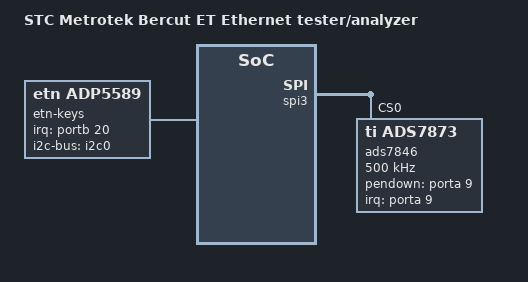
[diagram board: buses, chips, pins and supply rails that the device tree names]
/*
 * Copyright Altera Corporation (C) 2012,2014. All rights reserved.
 *
 * This program is free software; you can redistribute it and/or modify
 * it under the terms and conditions of the GNU General Public License,
 * version 2, as published by the Free Software Foundation.
 *
 * This program is distributed in the hope it will be useful, but WITHOUT
 * ANY WARRANTY; without even the implied warranty of MERCHANTABILITY or
 * FITNESS FOR A PARTICULAR PURPOSE.  See the GNU General Public License for
 * more details.
 *
 * You should have received a copy of the GNU General Public License along with
 * this program.  If not, see <http://www.gnu.org/licenses/>.
 */

#include "socfpga_cyclone5_stcmtk_som.dtsi"
#include <dt-bindings/input/input.h>
#include <dt-bindings/interrupt-controller/irq.h>
#include <dt-bindings/gpio/gpio.h>

/ {
	model = "STC Metrotek Bercut ET Ethernet tester/analyzer";

	soc {
		i2c0: i2c@ffc04000 {
			scl-gpios = <&portb 27 GPIO_ACTIVE_HIGH>;
			sda-gpios = <&portb 26 GPIO_ACTIVE_HIGH>;
		};

		etn-keys {
			compatible = "etn,adp5589";
			i2c-bus = <&i2c0>;
			addr = <0x34>;
			interrupt-parent = <&portb>;
			interrupts = <20 2>;
			adp5589,scan-cycle-time-ms = <40>;
			adp5589,pullup-300k = < (~0) >;
			linux,autorepeat-delay = <500>; /* miliseconds */
			linux,autorepeat-period = <50>; /* miliseconds */
			linux,keymap = <
				MATRIX_KEY(0, 0, KEY_KPASTERISK)
				MATRIX_KEY(1, 0, KEY_7)
				MATRIX_KEY(2, 0, KEY_4)
				MATRIX_KEY(3, 0, KEY_1)
				MATRIX_KEY(4, 0, KEY_HOME)
				MATRIX_KEY(5, 0, KEY_LEFT)
				MATRIX_KEY(6, 0, KEY_ESC)
				MATRIX_KEY(7, 0, KEY_F1)
				MATRIX_KEY(0, 1, KEY_0)
				MATRIX_KEY(1, 1, KEY_8)
				MATRIX_KEY(2, 1, KEY_5)
				MATRIX_KEY(3, 1, KEY_2)
				MATRIX_KEY(4, 1, KEY_DOWN)
				MATRIX_KEY(5, 1, KEY_UP)
				MATRIX_KEY(6, 1, KEY_F2)
				MATRIX_KEY(7, 1, KEY_F3)
				MATRIX_KEY(0, 2, KEY_GRAVE)
				MATRIX_KEY(1, 2, KEY_9)
				MATRIX_KEY(2, 2, KEY_6)
				MATRIX_KEY(3, 2, KEY_3)
				MATRIX_KEY(4, 2, KEY_END)
				MATRIX_KEY(5, 2, KEY_RIGHT)
				MATRIX_KEY(6, 2, KEY_ENTER)
				MATRIX_KEY(7, 2, KEY_F4)
				>;
		};
		
		etn-fb {
			compatible = "etn,fb";
			etn-fb,fps = <100>;
			etn-fb,use_fpga2sdram;
		};
	};

	spi3 {
		ads7846@0 {
			compatible = "ti,ads7873";
			reg = <0>;
			interrupt-parent = <&porta>;
			interrupts = <9 IRQ_TYPE_EDGE_FALLING>;
			ti,keep-vref-on;
			pendown-gpio = <&porta 9 IRQ_TYPE_EDGE_FALLING>;
			spi-max-frequency = <500000>;
			enable-dma = <1>;
			ti,vref-delay-usecs = /bits/ 16 <200>;
			ti,x-min = /bits/ 16 <0x0>;
			ti,x-max = /bits/ 16 <0x0fff>;
			ti,y-min = /bits/ 16 <0x0>;
			ti,y-max = /bits/ 16 <0x0fff>;

			ti,x-plate-ohms = /bits/ 16 <180>;
			ti,pressure-max = /bits/ 16 <255>;

			ti,debounce-max = /bits/ 16 <30>;
			ti,debounce-tol = /bits/ 16 <10>;
			ti,debounce-rep = /bits/ 16 <1>;
			ti,pendown-gpio-debounce = /bits/ 16 <100>;
			linux,wakeup;
		};
	};
};
